# WS63 register map
File version: 1.0
CPU: other r0p0, little endian, MPU, FPU, 3 interrupt priority bits
Registers are 32-bit, read-write, reset 0x0 unless marked. A register's access mark holds for its fields unless they carry their own. Offsets are from the block's base; [hi:lo] are bit positions; {n}, {i} and the like mark numbered series.

## TRNG — True Random Number Generator
Base 0x44114000
0x100 TRNG_FIFO_DATA — TRNG FIFO data output register
  [31:0] trng_data ro — Random data (read to get random number)
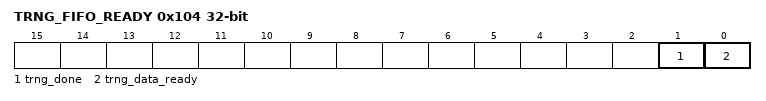
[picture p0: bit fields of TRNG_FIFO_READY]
0x104 TRNG_FIFO_READY — TRNG FIFO ready status
  [1] trng_done ro — TRNG generation done
  [0] trng_data_ready ro — Data ready: 1=data available in FIFO
0x108 TRNG_DATA_ST — TRNG data status register
  [31:0] data_st ro — Data status
0x174 TRNG_FRO_SAMPLE_CLK_SEL — TRNG FRO sample clock select
  [0] fro_sample_clk_sel — FRO sample clock select: 0=inner; 1=external
0x178 TRNG_FRO_DIV_CNT — TRNG FRO divider count
  [7:0] fro_div_cnt — FRO divider count (default 0x1b)

## TCXO — TCXO 64-bit free-running counter (v150)
Base 0x440004C0
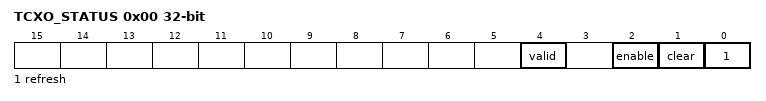
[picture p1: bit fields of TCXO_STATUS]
0x00 TCXO_STATUS — TCXO status and control register
  [4] valid ro — TCXO count value valid flag
  [2] enable — TCXO count enable: 1=enable counting
  [1] clear — TCXO count clear: 1=clear counter
  [0] refresh — TCXO count refresh: 1=trigger count latch
{0x4+4i} TCXO_COUNT{i} (i=0..3) — TCXO count bits [{16i+15}:{16i}]
  [15:0] count{i} ro — Counter value bits [{16i+15}:{16i}]

## CLDO_CRG — CLDO Clock and Reset Generator - clock enables, dividers, clock selects, soft resets
Base 0x44001100
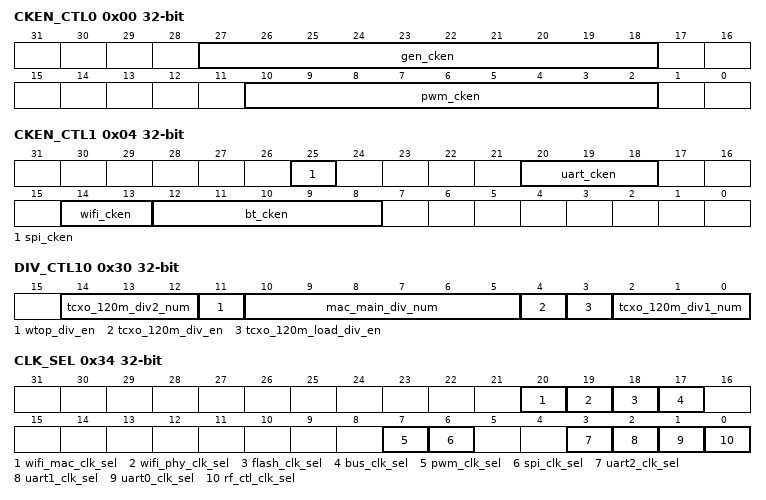
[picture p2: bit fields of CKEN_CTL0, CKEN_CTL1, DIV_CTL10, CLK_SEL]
0x00 CKEN_CTL0 — Clock enable control register 0
  [27:18] gen_cken — General clock gates: bits [27:18], 10 channels
  [10:2] pwm_cken — PWM clock gates: bits [10:2], 9 channels
0x04 CKEN_CTL1 — Clock enable control register 1
  [25] spi_cken — SPI clock gate at bit 25
  [20:18] uart_cken — UART clock gates: bits [20:18], 3 channels
  [14:13] wifi_cken — WIFI clock gates: bits [14:13], 2 channels
  [12:8] bt_cken — BT clock gates: bits [12:8], 5 channels
0x08 DIV_CTL0 — Divider control register 0
  [31:0] div_ctl0 — Clock divider control 0
0x14 DIV_CTL3 — Divider control 3 - PWM0, PWM1
  [31:0] div_pwm01 — PWM0/PWM1 clock divider
0x18 DIV_CTL4 — Divider control 4 - PWM2, PWM3, PWM4
  [31:0] div_pwm234 — PWM2/PWM3/PWM4 clock divider
0x1C DIV_CTL5 — Divider control 5 - PWM5, PWM6, PWM7
  [31:0] div_pwm567 — PWM5/PWM6/PWM7 clock divider
0x24 DIV_CTL7 — Divider control 7 - tsensor, bus
  [31:0] div_tsensor_bus — TSENSOR and bus clock dividers
0x2C DIV_CTL9 — Divider control 9 - TRNG
  [31:0] div_trng — TRNG clock divider
0x30 DIV_CTL10 — Divider control 10 - TCXO 120M, MAC main
  [14:12] tcxo_120m_div2_num — TCXO 120M divider 2 value (3-bit)
  [11] wtop_div_en — WTO divider enable
  [10:5] mac_main_div_num — MAC main divider value (6-bit)
  [4] tcxo_120m_div_en — TCXO 120M divider enable
  [3] tcxo_120m_load_div_en — TCXO 120M load divider enable
  [2:0] tcxo_120m_div1_num — TCXO 120M divider 1 value (3-bit)
0x34 CLK_SEL — Clock source select register
  [20] wifi_mac_clk_sel — WIFI_MAC clock select
  [19] wifi_phy_clk_sel — WIFI_PHY clock select
  [18] flash_clk_sel — Flash clock: 0=TCXO; 1=PLL
  [17] bus_clk_sel — Bus clock select
  [7] pwm_clk_sel — PWM clock: 0=TCXO; 1=PLL
  [6] spi_clk_sel — SPI clock select
  [3] uart2_clk_sel — UART2 clock select
  [2] uart1_clk_sel — UART1 clock select
  [1] uart0_clk_sel — UART0 clock: 0=TCXO; 1=PLL
  [0] rf_ctl_clk_sel — RF_CTL clock: 0=TCXO; 1=PLL
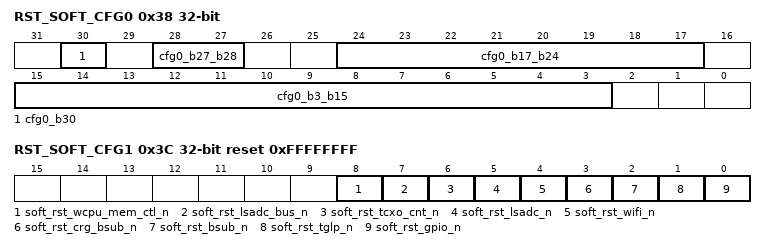
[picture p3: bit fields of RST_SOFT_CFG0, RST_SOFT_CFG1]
0x38 RST_SOFT_CFG0 — Soft reset configuration register 0
  [30] cfg0_b30 — Soft reset bit 30
  [28:27] cfg0_b27_b28 — 2-bit soft reset control (bits [28:27])
  [24:17] cfg0_b17_b24 — 8-bit soft reset control (bits [24:17])
  [15:3] cfg0_b3_b15 — 13-bit soft reset control (bits [15:3])
0x3C RST_SOFT_CFG1 reset 0xFFFFFFFF — Soft reset configuration register 1 (active low)
  [8] soft_rst_wcpu_mem_ctl_n — WCPU memory controller reset: 0=reset; 1=released
  [7] soft_rst_lsadc_bus_n — LSADC bus interface reset: 0=reset; 1=released
  [6] soft_rst_tcxo_cnt_n — TCXO counter reset: 0=reset; 1=released
  [5] soft_rst_lsadc_n — LSADC core reset: 0=reset; 1=released
  [4] soft_rst_wifi_n — WIFI subsystem reset: 0=reset; 1=released
  [3] soft_rst_crg_bsub_n — CRG BSUB (BT) reset: 0=reset; 1=released
  [2] soft_rst_bsub_n — BSUB (BT) reset: 0=reset; 1=released
  [1] soft_rst_tglp_n — TGLP (BT) reset: 0=reset; 1=released
  [0] soft_rst_gpio_n — GPIO module reset: 0=reset; 1=released

## RF_WB_CTL — SYS_CTL2 sub-block: RF Wideband Control Register Block - WL/BT RF analog interface control
Base 0x44004000
0x00 SYS_CTL_ID — System control ID register
0x10 RF_WL_REG_CLK_CTL — RF WL register clock control
0x14 RF_WL_REG_SOFT_RSTN — RF WL register soft reset
0x18 RF_WL_REG_CMD_SOFT_RSTN — RF WL command soft reset
0x1C RF_WL_REG_CMD_FIFO_STS — RF WL command FIFO status
0x20 RF_WL_CBB_DIS — RF WL CBB disable
0x24 RF_BT_CBB_DIS — RF BT CBB disable
0x30 ABB_ADC_CTRL — ABB ADC control
0x34 ABB_DAC_CTRL — ABB DAC control
0x38 ABB_EN_CTRL — ABB enable control
0x3C CFG_WL_ADC_MUX — WL ADC mux configuration
0x40 CFG_RF_MAN_EN_CTRL — RF manual enable control
0x44 CFG_TRXEN_CTRL — TRX enable control
0x48 CFG_DCOC_IQ_CTRL — DCOC IQ control
0x4C CFG_PA_IDX_CTRL — PA index control
0x50 CFG_LPF_CTRL — LPF control
0x54 CFG_RADAR_CTRL — Radar control
0x58 CFG_PPA_CODE — PPA code register
0x5C CFG_TEMP_LOCK_CTRL — Temperature lock control
0x60 CFG_TEMP_BANK_SEL_CTRL — Temperature bank select control
0x64 CFG_RF_DIAG_MUX — RF diagnostic mux

## SHARE_MEM_CTL — SYS_CTL2 sub-block: Shared Memory Control - RAM config, RX/TX DMA descriptor rings for WiFi PHY↔Packet buffer
Base 0x44006C00
0x04 CFG_RAM_CKEN — RAM clock enable
0x08 CFG_RAM_SEL — Share RAM control and RAM select
0x0C RAM_SW_CONFLICT_CLR — RAM software conflict clear
0x10 RAM_SW_CONFLICT_ST — RAM software conflict status
0x14 RAMX_SW_CONFLICT_BASE_ADDR — RAMX software conflict base address
0x50 CFG_FREQ_BUSDMAC — Bus DMAC frequency configuration
0x58 CFG_RX_EN — RX enable
0x5C CFG_RX_START_ADDR — RX start address
0x60 CFG_RX_END_ADDR — RX end address
0x64 CFG_RX_DONE_STS — RX done status
0x68 CFG_RX_DONE_ADDR — RX done address
0x6C CFG_WLPHY2PKT_RX_RAM_STS — WL PHY-to-packet RX RAM status
0x70 CFG_TX_EN — TX enable
0x74 CFG_TX_START_ADDR — TX start address
0x78 CFG_TX_END_ADDR — TX end address
0x7C CFG_TX_DONE_STS — TX done status
0x80 CFG_TX_DONE_ADDR — TX done address
0x84 CFG_WLPHY2PKT_TX_RAM_STS — WL PHY-to-packet TX RAM status

## FAMA_REMAP — SYS_CTL2 sub-block: Flash Address Map Remap - up to 12 regions for boot-time address redirection
Base 0x44007800
0x00 REMAP_SRC_BASE — Remap source base address (address >> 12). Up to 12 regions, offset 0x0 + 0x4*n
0x20 REMAP_LEN — Remap region length (end address >> 12). offset 0x20 + 0x4*n
0x40 REMAP_DST_BASE — Remap destination base offset (dest - src). offset 0x40 + 0x4*n
